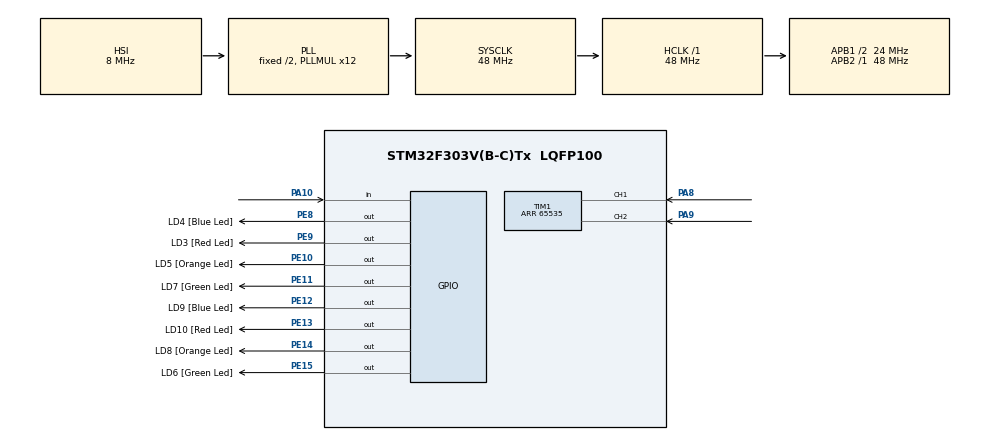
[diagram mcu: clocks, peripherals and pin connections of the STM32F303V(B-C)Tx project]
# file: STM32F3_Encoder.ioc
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Mcu.Family=STM32F3
Mcu.Name=STM32F303V(B-C)Tx
Mcu.Package=LQFP100
NVIC.PriorityGroup=NVIC_PRIORITYGROUP_0
PA10.Signal=GPIO_Input
PA11.GPIO_Label=DM
PA11.Signal=USB_DM
PA12.GPIO_Label=DP
PA12.Signal=USB_DP
PA13.GPIO_Label=SWDIO
PA13.Signal=SYS_JTMS-SWDIO
PA14.GPIO_Label=SWCLK
PA14.Signal=SYS_JTCK-SWCLK
PA8.GPIO_PuPd=GPIO_PULLUP
PA8.GPIO_Speed=GPIO_SPEED_FREQ_HIGH
PA8.Signal=S_TIM1_CH1
PA9.GPIO_PuPd=GPIO_PULLUP
PA9.GPIO_Speed=GPIO_SPEED_FREQ_HIGH
PA9.Signal=S_TIM1_CH2
PB3.GPIO_Label=SWO
PB3.Signal=SYS_JTDO-TRACESWO
PC14-OSC32_IN.GPIO_Label=OSC32_IN
PC14-OSC32_IN.Signal=RCC_OSC32_IN
PC15-OSC32_OUT.GPIO_Label=OSC32_OUT
PC15-OSC32_OUT.Signal=RCC_OSC32_OUT
PE10.GPIO_Label=LD5 [Orange Led]
PE10.GPIO_ModeDefaultOutputPP=GPIO_MODE_OUTPUT_PP
PE10.GPIO_PuPd=GPIO_NOPULL
PE10.GPIO_Speed=GPIO_SPEED_FREQ_LOW
PE10.Signal=GPIO_Output
PE11.GPIO_Label=LD7 [Green Led]
PE11.GPIO_ModeDefaultOutputPP=GPIO_MODE_OUTPUT_PP
PE11.GPIO_PuPd=GPIO_NOPULL
PE11.GPIO_Speed=GPIO_SPEED_FREQ_LOW
PE11.Signal=GPIO_Output
PE12.GPIO_Label=LD9 [Blue Led]
PE12.GPIO_ModeDefaultOutputPP=GPIO_MODE_OUTPUT_PP
PE12.GPIO_PuPd=GPIO_NOPULL
PE12.GPIO_Speed=GPIO_SPEED_FREQ_LOW
PE12.Signal=GPIO_Output
PE13.GPIO_Label=LD10 [Red Led]
PE13.GPIO_ModeDefaultOutputPP=GPIO_MODE_OUTPUT_PP
PE13.GPIO_PuPd=GPIO_NOPULL
PE13.GPIO_Speed=GPIO_SPEED_FREQ_LOW
PE13.Signal=GPIO_Output
PE14.GPIO_Label=LD8 [Orange Led]
PE14.GPIO_ModeDefaultOutputPP=GPIO_MODE_OUTPUT_PP
PE14.GPIO_PuPd=GPIO_NOPULL
PE14.GPIO_Speed=GPIO_SPEED_FREQ_LOW
PE14.Signal=GPIO_Output
PE15.GPIO_Label=LD6 [Green Led]
PE15.GPIO_ModeDefaultOutputPP=GPIO_MODE_OUTPUT_PP
PE15.GPIO_PuPd=GPIO_NOPULL
PE15.GPIO_Speed=GPIO_SPEED_FREQ_LOW
PE15.Signal=GPIO_Output
PE8.GPIO_Label=LD4 [Blue Led]
PE8.GPIO_ModeDefaultOutputPP=GPIO_MODE_OUTPUT_PP
PE8.GPIO_PuPd=GPIO_NOPULL
PE8.GPIO_Speed=GPIO_SPEED_FREQ_LOW
PE8.Signal=GPIO_Output
PE9.GPIO_Label=LD3 [Red Led]
PE9.GPIO_ModeDefaultOutputPP=GPIO_MODE_OUTPUT_PP
PE9.GPIO_PuPd=GPIO_NOPULL
PE9.GPIO_Speed=GPIO_SPEED_FREQ_LOW
PE9.Signal=GPIO_Output
PF0-OSC_IN.GPIO_Label=OSC_IN
PF0-OSC_IN.Signal=RCC_OSC_IN
PF1-OSC_OUT.GPIO_Label=OSC_OUT
PF1-OSC_OUT.Signal=RCC_OSC_OUT
ProjectManager.HeapSize=0x200
ProjectManager.StackSize=0x400
ProjectManager.TargetToolchain=SW4STM32
RCC.AHBFreq_Value=48000000
RCC.APB1CLKDivider=RCC_HCLK_DIV2
RCC.APB1Freq_Value=24000000
RCC.APB1TimFreq_Value=48000000
RCC.APB2Freq_Value=48000000
RCC.APB2TimFreq_Value=48000000
RCC.CortexFreq_Value=48000000
RCC.HCLKFreq_Value=48000000
RCC.HSE_VALUE=8000000
RCC.HSI_VALUE=8000000
RCC.LSE_VALUE=32768
RCC.PLLMUL=RCC_PLL_MUL12
RCC.SYSCLKFreq_VALUE=48000000
RCC.SYSCLKSourceVirtual=RCC_SYSCLKSOURCE_PLLCLK
RCC.USBFreq_Value=48000000
SH.S_TIM1_CH1.0=TIM1_CH1,Encoder_Interface
SH.S_TIM1_CH2.0=TIM1_CH2,Encoder_Interface
TIM1.EncoderMode=TIM_ENCODERMODE_TI12
TIM1.IC1Filter=0x0F
TIM1.IC1Prescaler=TIM_ICPSC_DIV4
TIM1.IC2Filter=0x0F
TIM1.IC2Polarity=TIM_ICPOLARITY_FALLING
TIM1.IC2Prescaler=TIM_ICPSC_DIV4
TIM1.Period=65535
board=STM32F3DISCOVERY

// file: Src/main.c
/**
  ******************************************************************************
  * File Name          : main.c
  * Description        : Main program body
  ******************************************************************************
  *
  * COPYRIGHT(c) 2016 STMicroelectronics
  *
  * Redistribution and use in source and binary forms, with or without modification,
  * are permitted provided that the following conditions are met:
  *   1. Redistributions of source code must retain the above copyright notice,
  *      this list of conditions and the following disclaimer.
  *   2. Redistributions in binary form must reproduce the above copyright notice,
  *      this list of conditions and the following disclaimer in the documentation
  *      and/or other materials provided with the distribution.
  *   3. Neither the name of STMicroelectronics nor the names of its contributors
  *      may be used to endorse or promote products derived from this software
  *      without specific prior written permission.
  *
  * THIS SOFTWARE IS PROVIDED BY THE COPYRIGHT HOLDERS AND CONTRIBUTORS "AS IS"
  * AND ANY EXPRESS OR IMPLIED WARRANTIES, INCLUDING, BUT NOT LIMITED TO, THE
  * IMPLIED WARRANTIES OF MERCHANTABILITY AND FITNESS FOR A PARTICULAR PURPOSE ARE
  * DISCLAIMED. IN NO EVENT SHALL THE COPYRIGHT HOLDER OR CONTRIBUTORS BE LIABLE
  * FOR ANY DIRECT, INDIRECT, INCIDENTAL, SPECIAL, EXEMPLARY, OR CONSEQUENTIAL
  * DAMAGES (INCLUDING, BUT NOT LIMITED TO, PROCUREMENT OF SUBSTITUTE GOODS OR
  * SERVICES; LOSS OF USE, DATA, OR PROFITS; OR BUSINESS INTERRUPTION) HOWEVER
  * CAUSED AND ON ANY THEORY OF LIABILITY, WHETHER IN CONTRACT, STRICT LIABILITY,
  * OR TORT (INCLUDING NEGLIGENCE OR OTHERWISE) ARISING IN ANY WAY OUT OF THE USE
  * OF THIS SOFTWARE, EVEN IF ADVISED OF THE POSSIBILITY OF SUCH DAMAGE.
  *
  ******************************************************************************
  */
#include "stm32f3xx_hal.h"

TIM_HandleTypeDef htim1;

/* USER CODE BEGIN PV */
/* Private variables ---------------------------------------------------------*/

uint32_t c = 0;

/* USER CODE END PV */

void SystemClock_Config(void);
void Error_Handler(void);
static void MX_GPIO_Init(void);
static void MX_TIM1_Init(void);

/* USER CODE BEGIN PFP */
/* Private function prototypes -----------------------------------------------*/

/* USER CODE END PFP */

int main(void)
{

  /* MCU Configuration----------------------------------------------------------*/

  /* Reset of all peripherals, Initializes the Flash interface and the Systick. */
  HAL_Init();

  /* Configure the system clock */
  SystemClock_Config();

  /* Initialize all configured peripherals */
  MX_GPIO_Init();
  MX_TIM1_Init();

  /* USER CODE BEGIN 2 */

  HAL_TIM_Encoder_Start(&htim1, TIM_CHANNEL_1 | TIM_CHANNEL_2);

  /* USER CODE END 2 */

  /* Infinite loop */
  while (1)
  {

  /* USER CODE BEGIN 3 */
	  c = __HAL_TIM_GET_COUNTER(&htim1);
	  printf("%d\n", c);
	  HAL_Delay(250);

  }
  /* USER CODE END 3 */

}

/** System Clock Configuration
*/
void SystemClock_Config(void)
{

  RCC_OscInitTypeDef RCC_OscInitStruct;
  RCC_ClkInitTypeDef RCC_ClkInitStruct;
  RCC_PeriphCLKInitTypeDef PeriphClkInit;

  RCC_OscInitStruct.OscillatorType = RCC_OSCILLATORTYPE_HSI;
  RCC_OscInitStruct.HSIState = RCC_HSI_ON;
  RCC_OscInitStruct.HSICalibrationValue = 16;
  RCC_OscInitStruct.PLL.PLLState = RCC_PLL_ON;
  RCC_OscInitStruct.PLL.PLLSource = RCC_PLLSOURCE_HSI;
  RCC_OscInitStruct.PLL.PLLMUL = RCC_PLL_MUL12;
  if (HAL_RCC_OscConfig(&RCC_OscInitStruct) != HAL_OK)
  {
    Error_Handler();
  }

  RCC_ClkInitStruct.ClockType = RCC_CLOCKTYPE_HCLK|RCC_CLOCKTYPE_SYSCLK
                              |RCC_CLOCKTYPE_PCLK1|RCC_CLOCKTYPE_PCLK2;
  RCC_ClkInitStruct.SYSCLKSource = RCC_SYSCLKSOURCE_PLLCLK;
  RCC_ClkInitStruct.AHBCLKDivider = RCC_SYSCLK_DIV1;
  RCC_ClkInitStruct.APB1CLKDivider = RCC_HCLK_DIV2;
  RCC_ClkInitStruct.APB2CLKDivider = RCC_HCLK_DIV1;
  if (HAL_RCC_ClockConfig(&RCC_ClkInitStruct, FLASH_LATENCY_1) != HAL_OK)
  {
    Error_Handler();
  }

  PeriphClkInit.PeriphClockSelection = RCC_PERIPHCLK_TIM1;
  PeriphClkInit.Tim1ClockSelection = RCC_TIM1CLK_HCLK;
  if (HAL_RCCEx_PeriphCLKConfig(&PeriphClkInit) != HAL_OK)
  {
    Error_Handler();
  }

  HAL_SYSTICK_Config(HAL_RCC_GetHCLKFreq()/1000);

  HAL_SYSTICK_CLKSourceConfig(SYSTICK_CLKSOURCE_HCLK);

  /* SysTick_IRQn interrupt configuration */
  HAL_NVIC_SetPriority(SysTick_IRQn, 0, 0);
}

/* TIM1 init function */
static void MX_TIM1_Init(void)
{

  TIM_Encoder_InitTypeDef sConfig;
  TIM_MasterConfigTypeDef sMasterConfig;

  htim1.Instance = TIM1;
  htim1.Init.Prescaler = 0;
  htim1.Init.CounterMode = TIM_COUNTERMODE_UP;
  htim1.Init.Period = 65535;
  htim1.Init.ClockDivision = TIM_CLOCKDIVISION_DIV1;
  htim1.Init.RepetitionCounter = 0;
  sConfig.EncoderMode = TIM_ENCODERMODE_TI12;
  sConfig.IC1Polarity = TIM_ICPOLARITY_RISING;
  sConfig.IC1Selection = TIM_ICSELECTION_DIRECTTI;
  sConfig.IC1Prescaler = TIM_ICPSC_DIV4;
  sConfig.IC1Filter = 0x0F;
  sConfig.IC2Polarity = TIM_ICPOLARITY_FALLING;
  sConfig.IC2Selection = TIM_ICSELECTION_DIRECTTI;
  sConfig.IC2Prescaler = TIM_ICPSC_DIV4;
  sConfig.IC2Filter = 0x0F;
  if (HAL_TIM_Encoder_Init(&htim1, &sConfig) != HAL_OK)
  {
    Error_Handler();
  }

  sMasterConfig.MasterOutputTrigger = TIM_TRGO_RESET;
  sMasterConfig.MasterOutputTrigger2 = TIM_TRGO2_RESET;
  sMasterConfig.MasterSlaveMode = TIM_MASTERSLAVEMODE_DISABLE;
  if (HAL_TIMEx_MasterConfigSynchronization(&htim1, &sMasterConfig) != HAL_OK)
  {
    Error_Handler();
  }

}

/** Configure pins as
        * Analog
        * Input
        * Output
        * EVENT_OUT
        * EXTI
     PA11   ------> USB_DM
     PA12   ------> USB_DP
*/
static void MX_GPIO_Init(void)
{

  GPIO_InitTypeDef GPIO_InitStruct;

  /* GPIO Ports Clock Enable */
  __HAL_RCC_GPIOC_CLK_ENABLE();
  __HAL_RCC_GPIOF_CLK_ENABLE();
  __HAL_RCC_GPIOE_CLK_ENABLE();
  __HAL_RCC_GPIOA_CLK_ENABLE();
  __HAL_RCC_GPIOB_CLK_ENABLE();

  /*Configure GPIO pin Output Level */
  HAL_GPIO_WritePin(GPIOE, LD4_Pin|LD3_Pin|LD5_Pin|LD7_Pin
                          |LD9_Pin|LD10_Pin|LD8_Pin|LD6_Pin, GPIO_PIN_RESET);

  /*Configure GPIO pins : LD4_Pin LD3_Pin LD5_Pin LD7_Pin
                           LD9_Pin LD10_Pin LD8_Pin LD6_Pin */
  GPIO_InitStruct.Pin = LD4_Pin|LD3_Pin|LD5_Pin|LD7_Pin
                          |LD9_Pin|LD10_Pin|LD8_Pin|LD6_Pin;
  GPIO_InitStruct.Mode = GPIO_MODE_OUTPUT_PP;
  GPIO_InitStruct.Pull = GPIO_NOPULL;
  GPIO_InitStruct.Speed = GPIO_SPEED_FREQ_LOW;
  HAL_GPIO_Init(GPIOE, &GPIO_InitStruct);

  /*Configure GPIO pin : PA10 */
  GPIO_InitStruct.Pin = GPIO_PIN_10;
  GPIO_InitStruct.Mode = GPIO_MODE_INPUT;
  GPIO_InitStruct.Pull = GPIO_NOPULL;
  HAL_GPIO_Init(GPIOA, &GPIO_InitStruct);

  /*Configure GPIO pins : DM_Pin DP_Pin */
  GPIO_InitStruct.Pin = DM_Pin|DP_Pin;
  GPIO_InitStruct.Mode = GPIO_MODE_AF_PP;
  GPIO_InitStruct.Pull = GPIO_NOPULL;
  GPIO_InitStruct.Speed = GPIO_SPEED_FREQ_HIGH;
  GPIO_InitStruct.Alternate = GPIO_AF14_USB;
  HAL_GPIO_Init(GPIOA, &GPIO_InitStruct);

}

void Error_Handler(void)
{
  while(1)
  {
  }
}

/************************ (C) COPYRIGHT STMicroelectronics *****END OF FILE****/
